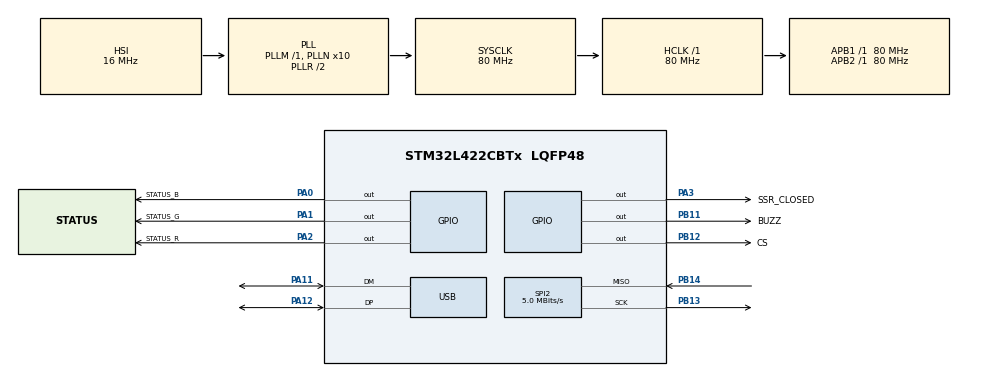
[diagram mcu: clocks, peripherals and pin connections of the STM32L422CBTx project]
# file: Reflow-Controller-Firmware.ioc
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Mcu.Family=STM32L4
Mcu.Name=STM32L422CBTx
Mcu.Package=LQFP48
NVIC.PriorityGroup=NVIC_PRIORITYGROUP_4
NVIC.USB_IRQn=true\:0\:0\:false\:false\:true\:false\:true\:true
PA0.GPIO_Label=STATUS_B
PA0.Signal=GPIO_Output
PA1.GPIO_Label=STATUS_G
PA1.Signal=GPIO_Output
PA11.Mode=Device
PA11.Signal=USB_DM
PA12.Mode=Device
PA12.Signal=USB_DP
PA13\ (JTMS/SWDIO).Mode=Trace_Asynchronous_SW
PA13\ (JTMS/SWDIO).Signal=SYS_JTMS-SWDIO
PA14\ (JTCK/SWCLK).Mode=Trace_Asynchronous_SW
PA14\ (JTCK/SWCLK).Signal=SYS_JTCK-SWCLK
PA2.GPIO_Label=STATUS_R
PA2.Signal=GPIO_Output
PA3.GPIO_Label=SSR_CLOSED
PA3.Signal=GPIO_Output
PB11.GPIO_Label=BUZZ
PB11.Signal=GPIO_Output
PB12.GPIO_Label=CS
PB12.Signal=GPIO_Output
PB13.Mode=RX_Only_Simplex_Unidirect_Master
PB13.Signal=SPI2_SCK
PB14.Mode=RX_Only_Simplex_Unidirect_Master
PB14.Signal=SPI2_MISO
PB3\ (JTDO/TRACESWO).Mode=Trace_Asynchronous_SW
PB3\ (JTDO/TRACESWO).Signal=SYS_JTDO-SWO
PH0-OSC_IN\ (PH0).Mode=HSE-External-Oscillator
PH0-OSC_IN\ (PH0).Signal=RCC_OSC_IN
PH1-OSC_OUT\ (PH1).Mode=HSE-External-Oscillator
PH1-OSC_OUT\ (PH1).Signal=RCC_OSC_OUT
ProjectManager.HeapSize=0x200
ProjectManager.StackSize=0x400
ProjectManager.TargetToolchain=CMake
RCC.ADCFreq_Value=80000000
RCC.AHBFreq_Value=80000000
RCC.APB1Freq_Value=80000000
RCC.APB1TimFreq_Value=80000000
RCC.APB2Freq_Value=80000000
RCC.APB2TimFreq_Value=80000000
RCC.CortexFreq_Value=80000000
RCC.HCLKFreq_Value=80000000
RCC.HSE_VALUE=8000000
RCC.HSI48_VALUE=48000000
RCC.HSI_VALUE=16000000
RCC.LSE_VALUE=32768
RCC.MSIClockRange=RCC_MSIRANGE_11
RCC.MSI_VALUE=48000000
RCC.PLLN=10
RCC.PLLSourceVirtual=RCC_PLLSOURCE_HSI
RCC.SYSCLKFreq_VALUE=80000000
RCC.SYSCLKSource=RCC_SYSCLKSOURCE_PLLCLK
RCC.USBFreq_Value=48000000
RCC.VCOOutputFreq_Value=160000000
SPI2.BaudRatePrescaler=SPI_BAUDRATEPRESCALER_16
SPI2.CalculateBaudRate=5.0 MBits/s
SPI2.DataSize=SPI_DATASIZE_8BIT
SPI2.Direction=SPI_DIRECTION_2LINES_RXONLY
SPI2.Mode=SPI_MODE_MASTER
SPI2.NSSPMode=SPI_NSS_PULSE_DISABLE
SPI2.VirtualType=VM_MASTER
USB_DEVICE.CLASS_NAME_FS=CDC
USB_DEVICE.VirtualMode=Cdc
USB_DEVICE.VirtualModeFS=Cdc_FS
VP_USB_DEVICE_VS_USB_DEVICE_CDC_FS.Mode=CDC_FS
board=custom

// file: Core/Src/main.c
/* USER CODE BEGIN Header */
/**
 ******************************************************************************
 * @file           : main.c
 * @brief          : Main program body
 ******************************************************************************
 * @attention
 *
 * <h2><center>&copy; Copyright (c) 2021 STMicroelectronics.
 * All rights reserved.</center></h2>
 *
 * This software component is licensed by ST under BSD 3-Clause license,
 * the "License"; You may not use this file except in compliance with the
 * License. You may obtain a copy of the License at:
 *                        opensource.org/licenses/BSD-3-Clause
 *
 ******************************************************************************
 */
/* USER CODE END Header */
#include "main.h"
#include "usb_device.h"

/* USER CODE BEGIN Includes */
#include "tasks.h"
/* USER CODE END Includes */

SPI_HandleTypeDef hspi2;

void SystemClock_Config(void);
static void MX_GPIO_Init(void);
static void MX_SPI2_Init(void);

int main(void)
{

  /* MCU Configuration--------------------------------------------------------*/

  /* Reset of all peripherals, Initializes the Flash interface and the Systick. */
  HAL_Init();

  /* Configure the system clock */
  SystemClock_Config();

  /* Initialize all configured peripherals */
  MX_GPIO_Init();
  MX_SPI2_Init();
  MX_USB_DEVICE_Init();
  /* USER CODE BEGIN 2 */
    task_init();
  /* USER CODE END 2 */

  /* Infinite loop */
  /* USER CODE BEGIN WHILE */
    for (;;) {
        task_superloop();
    }
    /* USER CODE END WHILE */

}

void SystemClock_Config(void)
{
  RCC_OscInitTypeDef RCC_OscInitStruct = {0};
  RCC_ClkInitTypeDef RCC_ClkInitStruct = {0};

  /** Configure the main internal regulator output voltage
  */
  if (HAL_PWREx_ControlVoltageScaling(PWR_REGULATOR_VOLTAGE_SCALE1) != HAL_OK)
  {
    Error_Handler();
  }

  /** Initializes the RCC Oscillators according to the specified parameters
  * in the RCC_OscInitTypeDef structure.
  */
  RCC_OscInitStruct.OscillatorType = RCC_OSCILLATORTYPE_HSI|RCC_OSCILLATORTYPE_MSI;
  RCC_OscInitStruct.HSIState = RCC_HSI_ON;
  RCC_OscInitStruct.HSICalibrationValue = RCC_HSICALIBRATION_DEFAULT;
  RCC_OscInitStruct.MSIState = RCC_MSI_ON;
  RCC_OscInitStruct.MSICalibrationValue = 0;
  RCC_OscInitStruct.MSIClockRange = RCC_MSIRANGE_11;
  RCC_OscInitStruct.PLL.PLLState = RCC_PLL_ON;
  RCC_OscInitStruct.PLL.PLLSource = RCC_PLLSOURCE_HSI;
  RCC_OscInitStruct.PLL.PLLM = 1;
  RCC_OscInitStruct.PLL.PLLN = 10;
  RCC_OscInitStruct.PLL.PLLQ = RCC_PLLQ_DIV2;
  RCC_OscInitStruct.PLL.PLLR = RCC_PLLR_DIV2;
  if (HAL_RCC_OscConfig(&RCC_OscInitStruct) != HAL_OK)
  {
    Error_Handler();
  }

  /** Initializes the CPU, AHB and APB buses clocks
  */
  RCC_ClkInitStruct.ClockType = RCC_CLOCKTYPE_HCLK|RCC_CLOCKTYPE_SYSCLK
                              |RCC_CLOCKTYPE_PCLK1|RCC_CLOCKTYPE_PCLK2;
  RCC_ClkInitStruct.SYSCLKSource = RCC_SYSCLKSOURCE_PLLCLK;
  RCC_ClkInitStruct.AHBCLKDivider = RCC_SYSCLK_DIV1;
  RCC_ClkInitStruct.APB1CLKDivider = RCC_HCLK_DIV1;
  RCC_ClkInitStruct.APB2CLKDivider = RCC_HCLK_DIV1;

  if (HAL_RCC_ClockConfig(&RCC_ClkInitStruct, FLASH_LATENCY_4) != HAL_OK)
  {
    Error_Handler();
  }
}

static void MX_SPI2_Init(void)
{

  /* SPI2 parameter configuration*/
  hspi2.Instance = SPI2;
  hspi2.Init.Mode = SPI_MODE_MASTER;
  hspi2.Init.Direction = SPI_DIRECTION_2LINES_RXONLY;
  hspi2.Init.DataSize = SPI_DATASIZE_8BIT;
  hspi2.Init.CLKPolarity = SPI_POLARITY_LOW;
  hspi2.Init.CLKPhase = SPI_PHASE_1EDGE;
  hspi2.Init.NSS = SPI_NSS_SOFT;
  hspi2.Init.BaudRatePrescaler = SPI_BAUDRATEPRESCALER_16;
  hspi2.Init.FirstBit = SPI_FIRSTBIT_MSB;
  hspi2.Init.TIMode = SPI_TIMODE_DISABLE;
  hspi2.Init.CRCCalculation = SPI_CRCCALCULATION_DISABLE;
  hspi2.Init.CRCPolynomial = 7;
  hspi2.Init.CRCLength = SPI_CRC_LENGTH_DATASIZE;
  hspi2.Init.NSSPMode = SPI_NSS_PULSE_DISABLE;
  if (HAL_SPI_Init(&hspi2) != HAL_OK)
  {
    Error_Handler();
  }

}

static void MX_GPIO_Init(void)
{
  GPIO_InitTypeDef GPIO_InitStruct = {0};

  /* GPIO Ports Clock Enable */
  __HAL_RCC_GPIOH_CLK_ENABLE();
  __HAL_RCC_GPIOA_CLK_ENABLE();
  __HAL_RCC_GPIOB_CLK_ENABLE();

  /*Configure GPIO pin Output Level */
  HAL_GPIO_WritePin(GPIOA, STATUS_B_Pin|STATUS_G_Pin|STATUS_R_Pin|SSR_CLOSED_Pin, GPIO_PIN_RESET);

  /*Configure GPIO pin Output Level */
  HAL_GPIO_WritePin(GPIOB, BUZZ_Pin|CS_Pin, GPIO_PIN_RESET);

  /*Configure GPIO pins : STATUS_B_Pin STATUS_G_Pin STATUS_R_Pin SSR_CLOSED_Pin */
  GPIO_InitStruct.Pin = STATUS_B_Pin|STATUS_G_Pin|STATUS_R_Pin|SSR_CLOSED_Pin;
  GPIO_InitStruct.Mode = GPIO_MODE_OUTPUT_PP;
  GPIO_InitStruct.Pull = GPIO_NOPULL;
  GPIO_InitStruct.Speed = GPIO_SPEED_FREQ_LOW;
  HAL_GPIO_Init(GPIOA, &GPIO_InitStruct);

  /*Configure GPIO pins : BUZZ_Pin CS_Pin */
  GPIO_InitStruct.Pin = BUZZ_Pin|CS_Pin;
  GPIO_InitStruct.Mode = GPIO_MODE_OUTPUT_PP;
  GPIO_InitStruct.Pull = GPIO_NOPULL;
  GPIO_InitStruct.Speed = GPIO_SPEED_FREQ_LOW;
  HAL_GPIO_Init(GPIOB, &GPIO_InitStruct);

}

void Error_Handler(void)
{
    __disable_irq();
    while (1) {
    }
}
